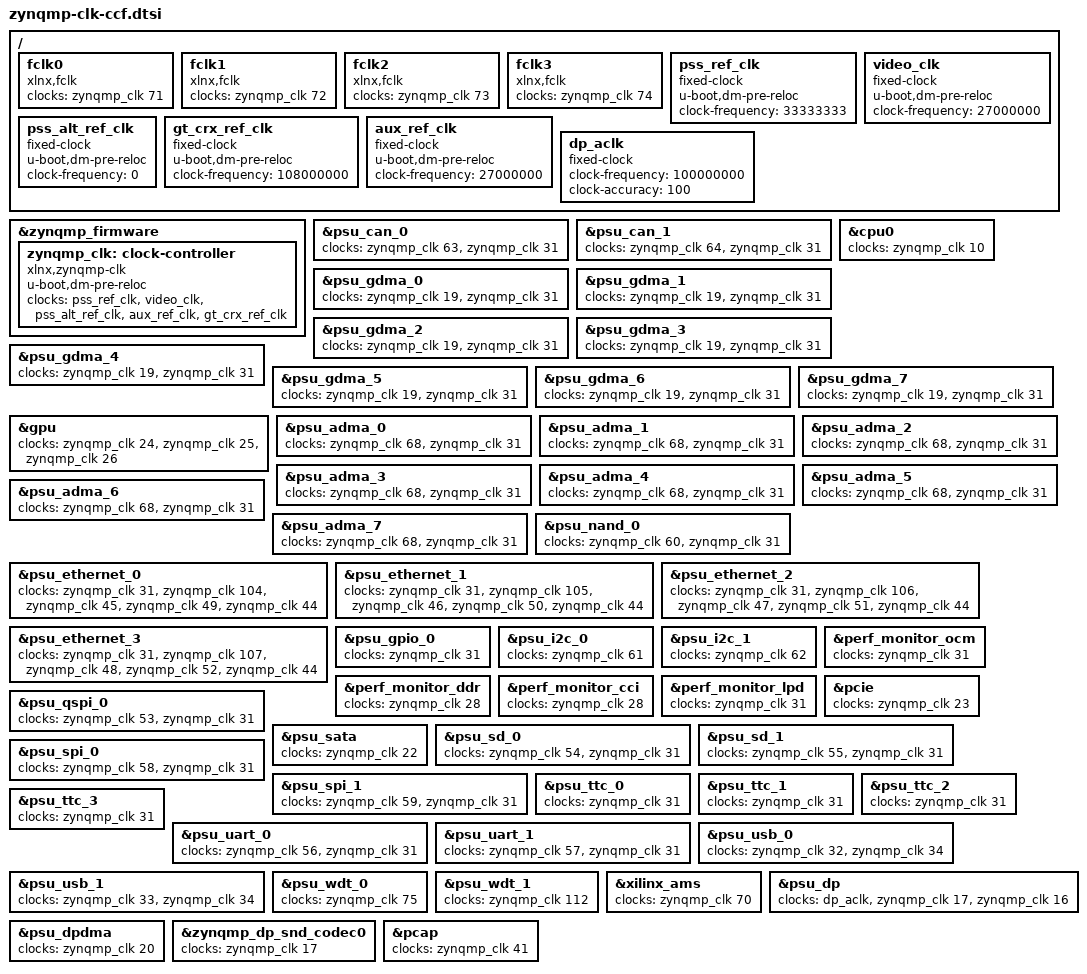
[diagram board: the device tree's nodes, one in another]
// SPDX-License-Identifier: GPL-2.0+
/*
 * Clock specification for Xilinx ZynqMP
 *
 * (C) Copyright 2017, Xilinx, Inc.
 *
 * Michal Simek <michal.simek@xilinx.com>
 */

/ {
	fclk0: fclk0 {
		status = "okay";
		compatible = "xlnx,fclk";
		clocks = <&zynqmp_clk 71>;
	};

	fclk1: fclk1 {
		status = "okay";
		compatible = "xlnx,fclk";
		clocks = <&zynqmp_clk 72>;
	};

	fclk2: fclk2 {
		status = "okay";
		compatible = "xlnx,fclk";
		clocks = <&zynqmp_clk 73>;
	};

	fclk3: fclk3 {
		status = "okay";
		compatible = "xlnx,fclk";
		clocks = <&zynqmp_clk 74>;
	};

	pss_ref_clk: pss_ref_clk {
		u-boot,dm-pre-reloc;
		compatible = "fixed-clock";
		#clock-cells = <0>;
		clock-frequency = <33333333>;
	};

	video_clk: video_clk {
		u-boot,dm-pre-reloc;
		compatible = "fixed-clock";
		#clock-cells = <0>;
		clock-frequency = <27000000>;
	};

	pss_alt_ref_clk: pss_alt_ref_clk {
		u-boot,dm-pre-reloc;
		compatible = "fixed-clock";
		#clock-cells = <0>;
		clock-frequency = <0>;
	};

	gt_crx_ref_clk: gt_crx_ref_clk {
		u-boot,dm-pre-reloc;
		compatible = "fixed-clock";
		#clock-cells = <0>;
		clock-frequency = <108000000>;
	};

	aux_ref_clk: aux_ref_clk {
		u-boot,dm-pre-reloc;
		compatible = "fixed-clock";
		#clock-cells = <0>;
		clock-frequency = <27000000>;
	};

	dp_aclk: dp_aclk {
		compatible = "fixed-clock";
		#clock-cells = <0>;
		clock-frequency = <100000000>;
		clock-accuracy = <100>;
	};
};

&zynqmp_firmware {
	zynqmp_clk: clock-controller {
		u-boot,dm-pre-reloc;
		#clock-cells = <1>;
		compatible = "xlnx,zynqmp-clk";
		clocks = <&pss_ref_clk>, <&video_clk>, <&pss_alt_ref_clk>,
			 <&aux_ref_clk>, <&gt_crx_ref_clk>;
		clock-names = "pss_ref_clk", "video_clk", "pss_alt_ref_clk",
			      "aux_ref_clk", "gt_crx_ref_clk";
	};
};

&psu_can_0 {
	clocks = <&zynqmp_clk 63>, <&zynqmp_clk 31>;
};

&psu_can_1 {
	clocks = <&zynqmp_clk 64>, <&zynqmp_clk 31>;
};

&cpu0 {
	clocks = <&zynqmp_clk 10>;
};

&psu_gdma_0 {
	clocks = <&zynqmp_clk 19>, <&zynqmp_clk 31>;
};

&psu_gdma_1 {
	clocks = <&zynqmp_clk 19>, <&zynqmp_clk 31>;
};

&psu_gdma_2 {
	clocks = <&zynqmp_clk 19>, <&zynqmp_clk 31>;
};

&psu_gdma_3 {
	clocks = <&zynqmp_clk 19>, <&zynqmp_clk 31>;
};

&psu_gdma_4 {
	clocks = <&zynqmp_clk 19>, <&zynqmp_clk 31>;
};

&psu_gdma_5 {
	clocks = <&zynqmp_clk 19>, <&zynqmp_clk 31>;
};

&psu_gdma_6 {
	clocks = <&zynqmp_clk 19>, <&zynqmp_clk 31>;
};

&psu_gdma_7 {
	clocks = <&zynqmp_clk 19>, <&zynqmp_clk 31>;
};

&gpu {
	clocks = <&zynqmp_clk 24>, <&zynqmp_clk 25>, <&zynqmp_clk 26>;
};

&psu_adma_0 {
	clocks = <&zynqmp_clk 68>, <&zynqmp_clk 31>;
};

&psu_adma_1 {
	clocks = <&zynqmp_clk 68>, <&zynqmp_clk 31>;
};

&psu_adma_2 {
	clocks = <&zynqmp_clk 68>, <&zynqmp_clk 31>;
};

&psu_adma_3 {
	clocks = <&zynqmp_clk 68>, <&zynqmp_clk 31>;
};

&psu_adma_4 {
	clocks = <&zynqmp_clk 68>, <&zynqmp_clk 31>;
};

&psu_adma_5 {
	clocks = <&zynqmp_clk 68>, <&zynqmp_clk 31>;
};

&psu_adma_6 {
	clocks = <&zynqmp_clk 68>, <&zynqmp_clk 31>;
};

&psu_adma_7 {
	clocks = <&zynqmp_clk 68>, <&zynqmp_clk 31>;
};

&psu_nand_0 {
	clocks = <&zynqmp_clk 60>, <&zynqmp_clk 31>;
};

&psu_ethernet_0 {
	clocks = <&zynqmp_clk 31>, <&zynqmp_clk 104>, <&zynqmp_clk 45>,
		 <&zynqmp_clk 49>, <&zynqmp_clk 44>;
	clock-names = "pclk", "hclk", "tx_clk", "rx_clk", "tsu_clk";
};

&psu_ethernet_1 {
	clocks = <&zynqmp_clk 31>, <&zynqmp_clk 105>, <&zynqmp_clk 46>,
		 <&zynqmp_clk 50>, <&zynqmp_clk 44>;
	clock-names = "pclk", "hclk", "tx_clk", "rx_clk", "tsu_clk";
};

&psu_ethernet_2 {
	clocks = <&zynqmp_clk 31>, <&zynqmp_clk 106>, <&zynqmp_clk 47>,
		 <&zynqmp_clk 51>, <&zynqmp_clk 44>;
	clock-names = "pclk", "hclk", "tx_clk", "rx_clk", "tsu_clk";
};

&psu_ethernet_3 {
	clocks = <&zynqmp_clk 31>, <&zynqmp_clk 107>, <&zynqmp_clk 48>,
		 <&zynqmp_clk 52>, <&zynqmp_clk 44>;
	clock-names = "pclk", "hclk", "tx_clk", "rx_clk", "tsu_clk";
};

&psu_gpio_0 {
	clocks = <&zynqmp_clk 31>;
};

&psu_i2c_0 {
	clocks = <&zynqmp_clk 61>;
};

&psu_i2c_1 {
	clocks = <&zynqmp_clk 62>;
};

&perf_monitor_ocm {
	clocks = <&zynqmp_clk 31>;
};

&perf_monitor_ddr {
	clocks = <&zynqmp_clk 28>;
};

&perf_monitor_cci {
	clocks = <&zynqmp_clk 28>;
};

&perf_monitor_lpd {
	clocks = <&zynqmp_clk 31>;
};

&pcie {
	clocks = <&zynqmp_clk 23>;
};

&psu_qspi_0 {
	clocks = <&zynqmp_clk 53>, <&zynqmp_clk 31>;
};

&psu_sata {
	clocks = <&zynqmp_clk 22>;
};

&psu_sd_0 {
	clocks = <&zynqmp_clk 54>, <&zynqmp_clk 31>;
};

&psu_sd_1 {
	clocks = <&zynqmp_clk 55>, <&zynqmp_clk 31>;
};

&psu_spi_0 {
	clocks = <&zynqmp_clk 58>, <&zynqmp_clk 31>;
};

&psu_spi_1 {
	clocks = <&zynqmp_clk 59>, <&zynqmp_clk 31>;
};

&psu_ttc_0 {
	clocks = <&zynqmp_clk 31>;
};

&psu_ttc_1 {
	clocks = <&zynqmp_clk 31>;
};

&psu_ttc_2 {
	clocks = <&zynqmp_clk 31>;
};

&psu_ttc_3 {
	clocks = <&zynqmp_clk 31>;
};

&psu_uart_0 {
	clocks = <&zynqmp_clk 56>, <&zynqmp_clk 31>;
};

&psu_uart_1 {
	clocks = <&zynqmp_clk 57>, <&zynqmp_clk 31>;
};

&psu_usb_0 {
	clocks = <&zynqmp_clk 32>, <&zynqmp_clk 34>;
};

&psu_usb_1 {
	clocks = <&zynqmp_clk 33>, <&zynqmp_clk 34>;
};

&psu_wdt_0 {
	clocks = <&zynqmp_clk 75>;
};

&psu_wdt_1 {
	clocks = <&zynqmp_clk 112>;
};

&xilinx_ams {
	clocks = <&zynqmp_clk 70>;
};

&psu_dp {
	clocks = <&dp_aclk>, <&zynqmp_clk 17>, <&zynqmp_clk 16>;
};

&psu_dpdma {
	clocks = <&zynqmp_clk 20>;
};

&zynqmp_dp_snd_codec0 {
	clocks = <&zynqmp_clk 17>;
};

&pcap {
	clocks = <&zynqmp_clk 41>;
};
